# RL6955_IP_SVD register map
Vendor: Realtek
Registers are 32-bit, read-write, reset 0x0 unless marked. A register's access mark holds for its fields unless they carry their own. Offsets are from the block's base; [hi:lo] are bit positions; {n}, {i} and the like mark numbered series.

## XTAL_REG
Base 0x40801400
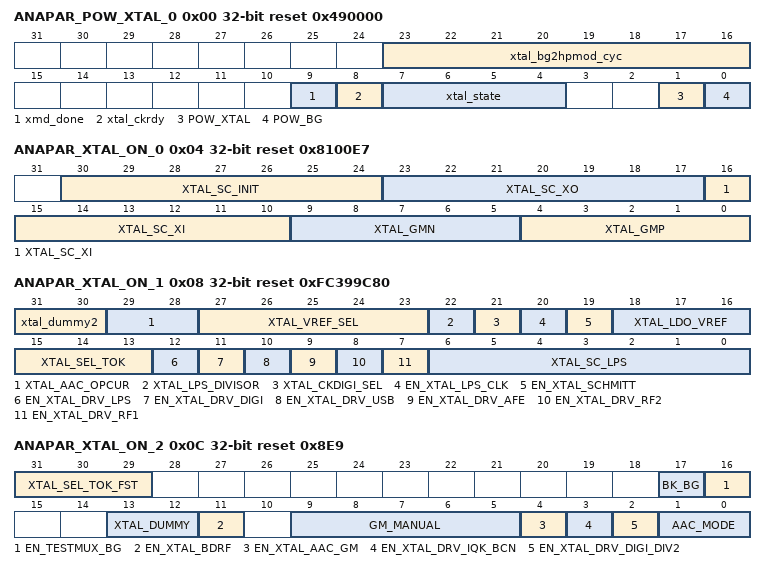
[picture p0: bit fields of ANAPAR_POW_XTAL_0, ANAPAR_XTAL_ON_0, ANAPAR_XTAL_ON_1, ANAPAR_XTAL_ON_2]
0x00 ANAPAR_POW_XTAL_0 access per field reset 0x490000
  [23:16] xtal_bg2hpmod_cyc rw — XTAL arb bandgap enable to hp mode delay cycle @4M
  [9] xmd_done ro — xmd change ok status
  [8] xtal_ckrdy ro — xtal clock ready status
  [7:4] xtal_state ro — 0 to 1 Enable xtal
  [1] POW_XTAL ro — 0 to 1 Enable xtal
  [0] POW_BG ro — Enable BG (BG for xtal and AFE) (有option關)
0x04 ANAPAR_XTAL_ON_0 reset 0x8100E7
  [30:24] XTAL_SC_INIT — 0: reduce cap, 1: increase cap. (220fF per unit) [efuse for BT only ] 有外掛電容設全0
  [23:17] XTAL_SC_XO — 1: reduce cap, 0: increase cap. (220fF per unit) [efuse for BT only ]
  [16:10] XTAL_SC_XI — 1: reduce cap, 0: increase cap. (220fF per unit) [efuse for BT only ]
  [9:5] XTAL_GMN — GMN: 0~31
  [4:0] XTAL_GMP — GMP: 0~31
0x08 ANAPAR_XTAL_ON_1 reset 0xFC399C80
  [31:30] xtal_dummy2 — Reserved for future use.
  [29:28] XTAL_AAC_OPCUR — 00: 200nA , 200n/step For AAC robust 11
  [27:23] XTAL_VREF_SEL — Analog AAC VREF, 390mV~700mV, 10mV/step 11000: Vpp 500mV
  [22] XTAL_LPS_DIVISOR — XTAL LPS clock divider 0: XTAL/128(40M), 1: XTAL/64
  [21] XTAL_CKDIGI_SEL — 1: DIGI CLK from self-bias 0: DIGI CLK from Schmitt
  [20] EN_XTAL_LPS_CLK — 1: enable XTAL LPS clock 與anapar_xtal_on[43]都是312.5KHz enable
  [19] EN_XTAL_SCHMITT — 1: enable XTAL SCHMITT
  [18:16] XTAL_LDO_VREF — (起震前) 111: 1.1V 110: 1.05V 101:1V 100:0.95V 011: 0.9V 010: 0.85V 001: 0.8V 000: 0.75V
  [15:13] XTAL_SEL_TOK — xtal起振过程 reg value: cycles / 40MHz / 26MHz 000: 2^10 / 0.025m / 0.05 001: 2^11 / 0.05m / 0.1m 010: 2^12 / 0.1m / 0.2m 011: 2^13 / 0.2m / 0.3m 100: 2^14 / 0.4m / 0.6m 101: 2^15 / 0.8m / 1.2m 110: 2^16 / 1.6m / 2.5m 111: 2^17 / 3.2m / 4.9m xtal mode switch过程 reg value: cycles / 40MHz / 26MHz 000: 2^10 / 0.0125m / 0.025 001: 2^11 / 0.025m / 0.05m 010: 2^12 / 0.05m / 0.1m 011: 2^13 / 0.1m / 0.2m 100: 2^14 / 0.2m / 0.3m 101: 2^15 / 0.4m / 0.6m 110: 2^16 / 0.8m / 1.25m 111: 2^17 / 1.6m / 2.45m
  [12] EN_XTAL_DRV_LPS — LPS enable clock source control, 1:enable, 0: gated 與anapar_xtal_on[51]都是312.5KHz enable
  [11] EN_XTAL_DRV_DIGI — DIGI enable clock source control, 1:enable, 0: gated
  [10] EN_XTAL_DRV_USB — USB enable clock source control, 1:enable, 0: gated
  [9] EN_XTAL_DRV_AFE — AFE enable clock source control, 1:enable, 0: gated (for WL AFE PLL)
  [8] EN_XTAL_DRV_RF2 — RF2 enable clock source control, 1:enable, 0: gated (for BT)
  [7] EN_XTAL_DRV_RF1 — RF1 enable clock source control, 1:enable, 0: gated (for WL SYN)
  [6:0] XTAL_SC_LPS — 0: reduce cap, 1: increase cap. (160fF per unit) [efuse for BT only ] 若有頻偏再修改
0x0C ANAPAR_XTAL_ON_2 reset 0x8E9
  [31:29] XTAL_SEL_TOK_FST — used for HP2NM or NM2HP xtal起振过程 reg value: cycles / 40MHz / 26MHz 000: 2^10 / 0.025m / 0.05 001: 2^11 / 0.05m / 0.1m 010: 2^12 / 0.1m / 0.2m 011: 2^13 / 0.2m / 0.3m 100: 2^14 / 0.4m / 0.6m 101: 2^15 / 0.8m / 1.2m 110: 2^16 / 1.6m / 2.5m 111: 2^17 / 3.2m / 4.9m xtal mode switch过程 reg value: cycles / 40MHz / 26MHz 000: 2^10 / 0.0125m / 0.025 001: 2^11 / 0.025m / 0.05m 010: 2^12 / 0.05m / 0.1m 011: 2^13 / 0.1m / 0.2m 100: 2^14 / 0.2m / 0.3m 101: 2^15 / 0.4m / 0.6m 110: 2^16 / 0.8m / 1.25m 111: 2^17 / 1.6m / 2.45m
  [17] BK_BG — RFTOP BG的 BK开关
  [16] EN_TESTMUX_BG — RFTOP BG的温度参数设定
  [13:12] XTAL_DUMMY — Dummy control bits
  [11] EN_XTAL_BDRF — Balance dynamic RF for duty cycle
  [9:5] GM_MANUAL — Gm manual at EN_XTAL_AAC_DIGI=0
  [4] EN_XTAL_AAC_GM — 1: enable xtal aac gm control
  [3] EN_XTAL_DRV_IQK_BCN — IQKPLL enable clock source control, 1:enable, 0: gate
  [2] EN_XTAL_DRV_DIGI_DIV2 — IQKPLL enable clock source control, 1:enable, 0: gate
  [1:0] AAC_MODE — AAC_MODE for LPS 00: all XOXI cap off 01: cap from XTAL_SC_LPS 10: cap from XTAL_SC_INIT 11: cap from XTAL_SC_XI/XO
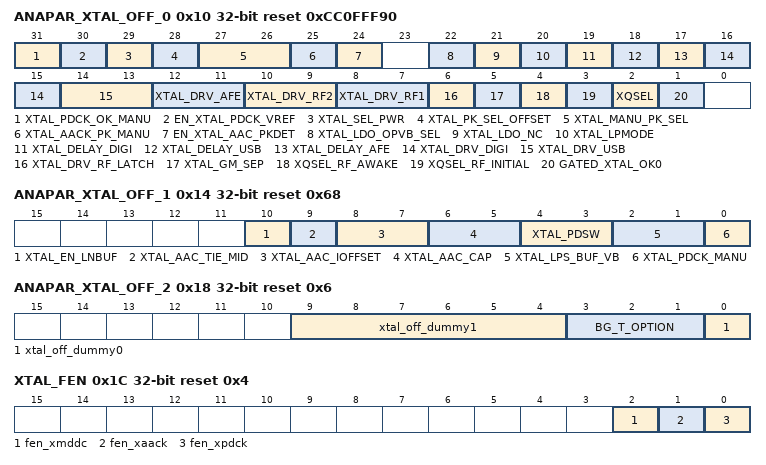
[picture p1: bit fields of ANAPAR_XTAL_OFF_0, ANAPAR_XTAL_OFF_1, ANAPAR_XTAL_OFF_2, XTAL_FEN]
0x10 ANAPAR_XTAL_OFF_0 reset 0xCC0FFF90
  [31] XTAL_PDCK_OK_MANU — 1: force PDCK_OK=1 for PDCK manual
  [30] EN_XTAL_PDCK_VREF — 1: analog AAC VREF from PDCK digital circuit 0: analog AAC VREF from XTAL_VREF_SEL for BT only mode
  [29] XTAL_SEL_PWR — 1: external 0.9V, 0: internal 0.9V (FIB)
  [28] XTAL_PK_SEL_OFFSET — 1: XI Vpk-to-Vpk offset to 00: 0.4V 01: 0.5V 10: 0.6V 11: 0.7V
  [27:26] XTAL_MANU_PK_SEL — XI Vpk-to-Vpk 00: 0.7V 01: 0.8V 10: 0.9V 11: 1V
  [25] XTAL_AACK_PK_MANU — 1: manual for peak detector peak selection
  [24] EN_XTAL_AAC_PKDET — 1: enable xtal aac peak detector
  [22] XTAL_LDO_OPVB_SEL — 0: OP bias from IBG, 1: OP bias from Res divider
  [21] XTAL_LDO_NC — 1: low current normal mode (22C) 0:high current normal mode (此pin要拉給BT控制)
  [20] XTAL_LPMODE — 1: low power mode enable 22C turn off replica path, RF1 no CLK RF2 sweep to LPS buf
  [19] XTAL_DELAY_DIGI — 1: turn on XI/XO Cfix, single side 8pF
  [18] XTAL_DELAY_USB — 0: short, 1:long
  [17] XTAL_DELAY_AFE — 0: short, 1:long
  [16:15] XTAL_DRV_DIGI — Driving control of DIGI/LPS clock buffer, 11:large current, 00: small current
  [14:13] XTAL_DRV_USB — Driving control of USB clock buffer, 11:large current, 00: small current
  [12:11] XTAL_DRV_AFE — Driving control of AFE clock buffer, 11:large current, 00: small current
  [10:9] XTAL_DRV_RF2 — Driving control of RF2 clock buffer, 11:large current, 00: small current
  [8:7] XTAL_DRV_RF1 — Dummy 由RFC控制
  [6] XTAL_DRV_RF_LATCH — 1: latch enable
  [5] XTAL_GM_SEP — 0: GMP=GMN
  [4] XQSEL_RF_AWAKE — 0: Schmitt trigger, 1:replica INV(for OK0=1)
  [3] XQSEL_RF_INITIAL — 0: Schmitt trigger, 1:replica INV(for OK0=0) 22C OK0=0, RF no CLK
  [2] XQSEL — 0: Schmitt trigger, 1:replica INV(for AFE)
  [1] GATED_XTAL_OK0 — 1:Gated xtal OK0
0x14 ANAPAR_XTAL_OFF_1 reset 0x68
  [10] XTAL_EN_LNBUF — 0: separate bias buffer (lower current higher noise) 1: self-bias (higher current lower noise)
  [9] XTAL_AAC_TIE_MID — XTAL_ AAC_TIE_MID=1 & EN_XTAL_PDCK_VREF=0 & using XTAL_VREF_SEL<4:0> for lock detect
  [8:7] XTAL_AAC_IOFFSET — Analog AAC IOFFSET current 00: off, 01:2uA, 10:4uA, 11:6uA
  [6:5] XTAL_AAC_CAP — Analog AAC domain pole cap 3pF/step 00: no cap,11: max cap
  [4:3] XTAL_PDSW — XTAL analog AAC peak detector source follower size, 00: small 11: large
  [2:1] XTAL_LPS_BUF_VB — 00: small current, 11: large current
  [0] XTAL_PDCK_MANU — 1: open analog AAC loop for PDCK manual
0x18 ANAPAR_XTAL_OFF_2 reset 0x6
  [9:4] xtal_off_dummy1 — HW used only
  [3:1] BG_T_OPTION — BG options
  [0] xtal_off_dummy0 — HW used only
0x1C XTAL_FEN reset 0x4
  [2] fen_xmddc — 1:enable xmddc 0:reset xmddc module
  [1] fen_xaack — 1:enable AACK 0:reset AACK module
  [0] fen_xpdck — 1:enable PDCK 0:reset PDCK module
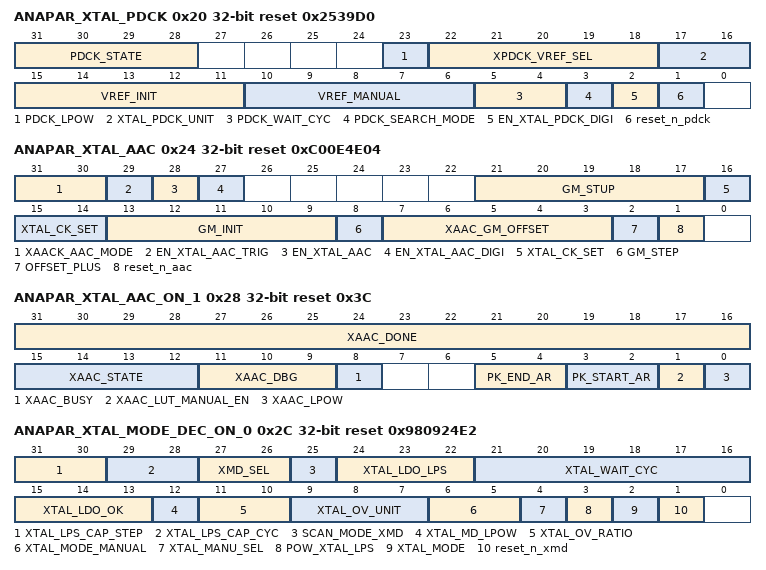
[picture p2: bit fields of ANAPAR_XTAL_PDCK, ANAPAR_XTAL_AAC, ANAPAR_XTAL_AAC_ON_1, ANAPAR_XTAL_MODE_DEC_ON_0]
0x20 ANAPAR_XTAL_PDCK access per field reset 0x2539D0
  [31:28] PDCK_STATE ro — PDCK state for debug
  [23] PDCK_LPOW rw — PDCK low power mode, 1:gating input clk Set to 1 when PDCK finished
  [22:18] XPDCK_VREF_SEL rw — PDCK calibrated result +offset For AAC robust +3
  [17:16] XTAL_PDCK_UNIT rw — PDCK settling cycles (4M CLK) 00: 4us 01: 8us 10: 16us 11: 32us
  [15:11] VREF_INIT rw — PDCK VREF initial setting
  [10:6] VREF_MANUAL rw — VREF manual at EN_XTAL_PDCK_DIGI=0 When pdck done, it will auto set this value to pdck result
  [5:4] PDCK_WAIT_CYC rw — Enable PDCK waiting (4M CLK) 00: 64us 01:128us 10:256us 11:512us
  [3] PDCK_SEARCH_MODE rw — 0: binary search, 1: full search from 31
  [2] EN_XTAL_PDCK_DIGI rw — Default set 0 due to POW_XTAL will 1 before do PDCK
  [1] reset_n_pdck rw — PDCK digital circuit reset (low to high),not used
0x24 ANAPAR_XTAL_AAC reset 0xC00E4E04
  [31:30] XAACK_AAC_MODE — 11: XTAL_AACK_PK_SEL=<11>'s XTAL_GM_OUT3 10: XTAL_AACK_PK_SEL=<10>'s XTAL_GM_OUT2 01: XTAL_AACK_PK_SEL=<01>'s XTAL_GM_OUT1 00: XTAL_AACK_PK_SEL=<00>'s XTAL_GM_OUT0
  [29] EN_XTAL_AAC_TRIG — MAC內部訊號(目前floating) Set by pmc and clr by HW finish calibration
  [28] EN_XTAL_AAC — MAC內部訊號(目前floating) 0: 不做AAC (default), 1: power on 做AAC
  [27] EN_XTAL_AAC_DIGI — 1:enable aac digital circuit
  [21:17] GM_STUP — aac gm start up setting (pkdet=0時,回到最大gm)
  [16:14] XTAL_CK_SET — aac settling cycles (4M CLK) 000: 64us 001: 128us 010: 256us 011: 512us 100: 1024us 101: 2048us 110: 4096us 111: 8192us
  [13:9] GM_INIT — aac gm initial setting
  [8] GM_STEP — aac gm searching step. 0:step 1, 1:step 2
  [7:3] XAAC_GM_OFFSET — aac calibrated gm result +/- offset
  [2] OFFSET_PLUS — 0: aac calibrated gm result -offset , 1:aac calibrated gm result + offset
  [1] reset_n_aac — AAC digital circuit reset (low to high) Default=0, 有EN_AAC 才會放開 (not used)
0x28 ANAPAR_XTAL_AAC_ON_1 access per field reset 0x3C
  [31:16] XAAC_DONE ro — for XAAC debug
  [15:12] XAAC_STATE ro — for XAAC debug
  [11:9] XAAC_DBG ro — for XAAC debug
  [8] XAAC_BUSY ro — for XAAC debug
  [5:4] PK_END_AR rw — AAC peak sel end (star>end)
  [3:2] PK_START_AR rw — AACK peak sel start (star>end)
  [1] XAAC_LUT_MANUAL_EN rw — 1: enable LUT data: GM_MANUAL<4:0> , sel: AAC_MODE<1:0>
  [0] XAAC_LPOW rw — AACK low power mode, 1:gating input clk
0x2C ANAPAR_XTAL_MODE_DEC_ON_0 access per field reset 0x980924E2
  [31:30] XTAL_LPS_CAP_STEP rw — 00:1 step/01:2 step/10:4 step /11:8 step 一次降幾檔Cap
  [29:28] XTAL_LPS_CAP_CYC rw — 00:8u/01:16u/10:32u/11:64u 多久降一次Cap step
  [27:26] XMD_SEL rw — 00:100K/01:500K/10:4M/11:12M 隨著系統頻率變化,需要改變此reg
  [25] SCAN_MODE_XMD rw — 1:scan mode
  [24:22] XTAL_LDO_LPS rw — (起震後, 進入LPS時) 111: 1.1V 110: 1.05V 101:1V 100:0.95V 011: 0.9V 010: 0.85V 001: 0.8V 000: 0.75V
  [21:16] XTAL_WAIT_CYC rw — Next state wait cycle, 83ns/unit
  [15:13] XTAL_LDO_OK rw — (起震後) 111: 1.1V 110: 1.05V 101:1V 100:0.95V 011: 0.9V 010: 0.85V 001: 0.8V 000: 0.75V
  [12] XTAL_MD_LPOW rw — XTAL mode decoder low power mode 1: gated input clock
  [11:10] XTAL_OV_RATIO rw — overlap unit times (4M CLK) 00: 128us 01: 256us 10: 512us 11: 1024us
  [9:7] XTAL_OV_UNIT rw — overlap time settling cycles (4M CLK) 000: 10us 001: 20us 010: 40us 011: 80us 100: 160us 101: 320us 110: 640us 111: 1280us
  [6:5] XTAL_MODE_MANUAL rw — 01: LPS mode 10: Normal mode 11: high performance mode [efuse for power on ]
  [4] XTAL_MANU_SEL rw — 1: enable xtal mode manual [efuse for power on ]
  [3] POW_XTAL_LPS ro
  [2] XTAL_MODE ro — 22C xtal mode define: {POW_XTAL, XTAL_MODE, POW_XTAL_LPS} [efuse for power on ]
  [1] reset_n_xmd rw — Decoder digital circuit reset (low to high) Default 1&POR 再給reset_n. (not used)
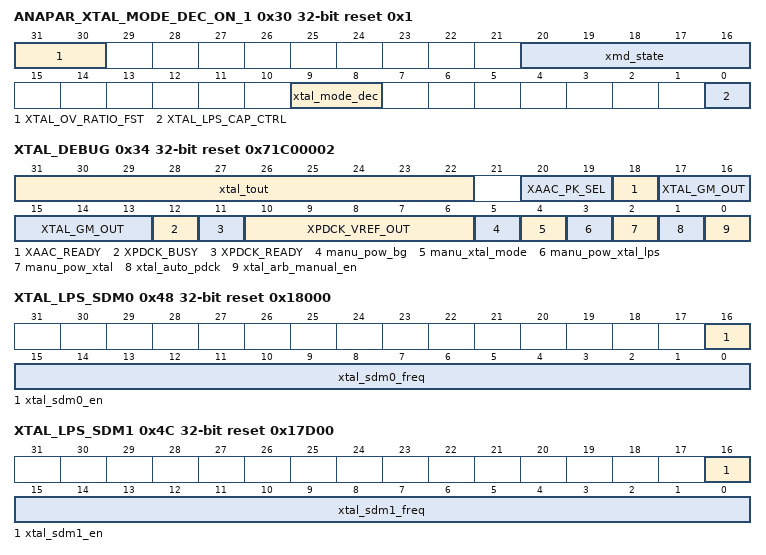
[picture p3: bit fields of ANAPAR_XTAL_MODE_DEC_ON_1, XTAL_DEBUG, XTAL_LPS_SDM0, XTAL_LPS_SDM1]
0x30 ANAPAR_XTAL_MODE_DEC_ON_1 access per field reset 0x1
  [31:30] XTAL_OV_RATIO_FST rw — overlap unit times (4M CLK), used for HP2NM or NM2HP 00: 128us 01: 256us 10: 512us 11: 1024us
  [20:16] xmd_state ro — for xmd debug
  [9:8] xtal_mode_dec ro — for xmd debug 10:NM 01: LPS 11: HP
  [0] XTAL_LPS_CAP_CTRL rw — 1:cap step control
0x34 XTAL_DEBUG access per field reset 0x71C00002
  [31:22] xtal_tout rw — xtal arbiter wait feedback signal timeout delay cycle, if this valua is max, arbiter will disable timeout function. Time unit is xtal_tutime
  [20:19] XAAC_PK_SEL ro — XAAC_PK_SEL(AAC calibration address)
  [18] XAAC_READY ro — signal for xtal
  [17:13] XTAL_GM_OUT ro — AACK digital calculate result for ANA comparator
  [12] XPDCK_BUSY ro — signal for xtal
  [11] XPDCK_READY ro — signal for xtal
  [10:6] XPDCK_VREF_OUT ro — PDCK digital calculate result for ANA comparator
  [5] manu_pow_bg rw — manual mode POW_BG
  [4] manu_xtal_mode rw — manual mode XTAL_MODE
  [3] manu_pow_xtal_lps rw — manual mode POW_XTAL_LPS
  [2] manu_pow_xtal rw — manual mode POW_XTAL
  [1] xtal_auto_pdck rw — Auto PDCK enable signal. If set this bit, arbiter will do PDCK before XTAL enter LPS mode. Once PDCK done , this bit will auto set 0
  [0] xtal_arb_manual_en rw — Aribter manual mode enable
0x38 XTAL_ART_CKON_TIM reset 0xF
  [7:0] dummy — HW used only
0x40 XTAL_LPS_FREQ_NM reset 0x4C4B4
  [18:0] xtal_clk_freq_nm — xtal 312.5K freq in normal mode , all cap are valid , it is exactly 312.5K.
0x44 XTAL_LPS_FREQ_LPS reset 0x4C4B4
  [18:0] xtal_clk_freq_lps — xtal 312.5K freq in lps mode , cap maybe disable for power save , maximumly , freq will be 312.5K + 250ppm
0x48 XTAL_LPS_SDM0 reset 0x18000
  [16] xtal_sdm0_en — xtal lps sdm0 output enable Note : sdm0 used for system and wifi, default is 32768Hz.
  [15:0] xtal_sdm0_freq — xtal lps sdm0 output frequency, unit is Hz. Note : sdm0 used for system and wifi, default is 32768Hz.
0x4C XTAL_LPS_SDM1 reset 0x17D00
  [16] xtal_sdm1_en — xtal lps sdm1 output enable Note : sdm1 used for bt, default is 32000Hz.
  [15:0] xtal_sdm1_freq — xtal lps sdm1 output frequency, unit is Hz. Note : sdm1 used for system and wifi, default is 32000Hz.
